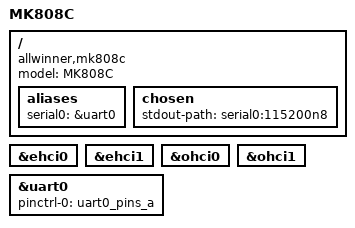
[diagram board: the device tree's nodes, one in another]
/*
 * Copyright 2015 Hans de Goede <hdegoede@redhat.com>
 *
 * Minimal dts file for the MK808C for u-boot only
 *
 * SPDX-License-Identifier:     GPL-2.0+ or X11
 */

/dts-v1/;
#include "sun7i-a20.dtsi"

/ {
	model = "MK808C";
	compatible = "allwinner,mk808c", "allwinner,sun7i-a20";

	aliases {
		serial0 = &uart0;
	};

	chosen {
		stdout-path = "serial0:115200n8";
	};
};

&ehci0 {
	status = "okay";
};

&ehci1 {
	status = "okay";
};

&ohci0 {
	status = "okay";
};

&ohci1 {
	status = "okay";
};

&uart0 {
	pinctrl-names = "default";
	pinctrl-0 = <&uart0_pins_a>;
	status = "okay";
};
